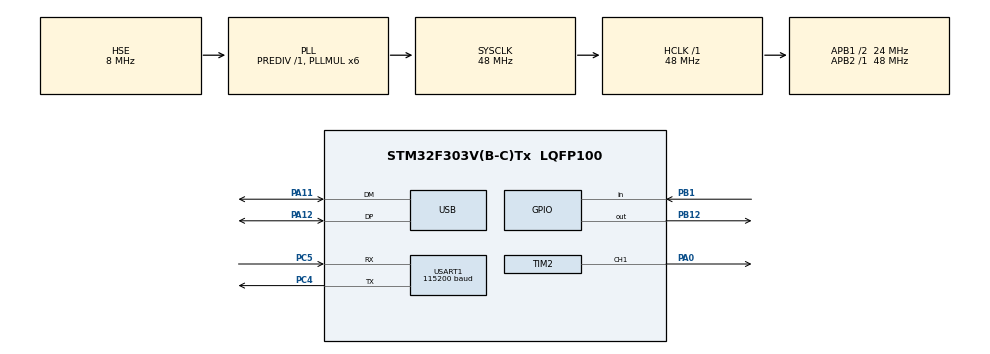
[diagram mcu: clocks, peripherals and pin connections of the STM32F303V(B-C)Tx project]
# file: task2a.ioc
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Mcu.Family=STM32F3
Mcu.Name=STM32F303V(B-C)Tx
Mcu.Package=LQFP100
NVIC.PriorityGroup=NVIC_PRIORITYGROUP_0
NVIC.USB_LP_CAN_RX0_IRQn=true\:0\:0\:false\:false\:true\:false\:true\:true
PA0.Signal=S_TIM2_CH1_ETR
PA11.Mode=Device
PA11.Signal=USB_DM
PA12.Mode=Device
PA12.Signal=USB_DP
PB1.Signal=GPIO_Input
PB12.Signal=GPIO_Output
PC4.Mode=Asynchronous
PC4.Signal=USART1_TX
PC5.Mode=Asynchronous
PC5.Signal=USART1_RX
PF0-OSC_IN.Mode=HSE-External-Oscillator
PF0-OSC_IN.Signal=RCC_OSC_IN
PF1-OSC_OUT.Mode=HSE-External-Oscillator
PF1-OSC_OUT.Signal=RCC_OSC_OUT
ProjectManager.HeapSize=0x200
ProjectManager.StackSize=0x400
ProjectManager.TargetToolchain=CMake
RCC.AHBFreq_Value=48000000
RCC.APB1CLKDivider=RCC_HCLK_DIV2
RCC.APB1Freq_Value=24000000
RCC.APB1TimFreq_Value=48000000
RCC.APB2Freq_Value=48000000
RCC.APB2TimFreq_Value=48000000
RCC.CortexFreq_Value=48000000
RCC.HCLKFreq_Value=48000000
RCC.HSE_VALUE=8000000
RCC.HSI_VALUE=8000000
RCC.LSE_VALUE=32768
RCC.PLLMUL=RCC_PLL_MUL6
RCC.PLLSourceVirtual=RCC_PLLSOURCE_HSE
RCC.SYSCLKFreq_VALUE=48000000
RCC.SYSCLKSourceVirtual=RCC_SYSCLKSOURCE_PLLCLK
RCC.USBFreq_Value=48000000
SH.S_TIM2_CH1_ETR.0=TIM2_CH1,PWM Generation1 CH1
TIM2.Channel-PWM\ Generation1\ CH1=TIM_CHANNEL_1
TIM2.Period=99
TIM2.Prescaler=47
TIM2.Pulse-PWM\ Generation1\ CH1=50
TIM3.Prescaler=71
USART1.BaudRate=115200
USART1.VirtualMode-Asynchronous=VM_ASYNC
USB_DEVICE.CLASS_NAME_FS=CDC
USB_DEVICE.VirtualMode=Cdc
USB_DEVICE.VirtualModeFS=Cdc_FS
VP_TIM2_VS_ClockSourceINT.Mode=Internal
VP_TIM3_VS_ClockSourceINT.Mode=Internal
VP_USB_DEVICE_VS_USB_DEVICE_CDC_FS.Mode=CDC_FS
board=STM32F3DISCOVERY

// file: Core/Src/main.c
/* USER CODE BEGIN Header */
/**
  ******************************************************************************
  * @file           : main.c
  * @brief          : Main program body
  ******************************************************************************
  * @attention
  *
  * Copyright (c) 2025 STMicroelectronics.
  * All rights reserved.
  *
  * This software is licensed under terms that can be found in the LICENSE file
  * in the root directory of this software component.
  * If no LICENSE file comes with this software, it is provided AS-IS.
  *
  ******************************************************************************
  */
/* USER CODE END Header */
#include "main.h"
#include "usb_device.h"

TIM_HandleTypeDef htim2;
TIM_HandleTypeDef htim3;

UART_HandleTypeDef huart1;

/* USER CODE BEGIN PV */
char msg[50];
float RPM = 0;
/* USER CODE END PV */

void SystemClock_Config(void);
static void MX_GPIO_Init(void);
static void MX_TIM2_Init(void);
static void MX_TIM3_Init(void);
static void MX_USART1_UART_Init(void);

int main(void)
{

  /* MCU Configuration--------------------------------------------------------*/

  /* Reset of all peripherals, Initializes the Flash interface and the Systick. */
  HAL_Init();

  /* Configure the system clock */
  SystemClock_Config();

  /* Initialize all configured peripherals */
  MX_GPIO_Init();
  MX_TIM2_Init();
  MX_TIM3_Init();
  MX_USART1_UART_Init();
  MX_USB_DEVICE_Init();
  /* USER CODE BEGIN 2 */

  HAL_TIM_PWM_Start(&htim2, TIM_CHANNEL_1);
  HAL_GPIO_WritePin(GPIOB, GPIO_PIN_12,1);

  /* USER CODE END 2 */

  /* Infinite loop */
  /* USER CODE BEGIN WHILE */
  while (1)
{
  // Wait for first edge
  while (HAL_GPIO_ReadPin(GPIOB, GPIO_PIN_1) == GPIO_PIN_RESET);
  while (HAL_GPIO_ReadPin(GPIOB, GPIO_PIN_1) == GPIO_PIN_SET); // Wait for falling edge

  __HAL_TIM_SET_COUNTER(&htim3, 0);               // Reset TIM3 counter
  HAL_TIM_Base_Start(&htim3);                     // Start timer

  // Wait for second edge
  while (HAL_GPIO_ReadPin(GPIOB, GPIO_PIN_1) == GPIO_PIN_RESET);
  while (HAL_GPIO_ReadPin(GPIOB, GPIO_PIN_1) == GPIO_PIN_SET); // Wait for falling edge again

  HAL_TIM_Base_Stop(&htim3);                      // Stop timer
  uint32_t captured_ticks = __HAL_TIM_GET_COUNTER(&htim3);  // Get the counter value

  float frequency = 0;
  if (captured_ticks != 0)
    frequency = 1000000.0f / captured_ticks;

  RPM = (frequency / 360.0f) * 60.0f;
  snprintf(msg, sizeof(msg), "Frequency = %.2f Hz, RPM = %.2f\r\n", frequency, RPM);
  HAL_UART_Transmit(&huart1, (uint8_t*)msg, strlen(msg), HAL_MAX_DELAY);

  /* USER CODE END 3 */
}

void SystemClock_Config(void)
{
  RCC_OscInitTypeDef RCC_OscInitStruct = {0};
  RCC_ClkInitTypeDef RCC_ClkInitStruct = {0};
  RCC_PeriphCLKInitTypeDef PeriphClkInit = {0};

  /** Initializes the RCC Oscillators according to the specified parameters
  * in the RCC_OscInitTypeDef structure.
  */
  RCC_OscInitStruct.OscillatorType = RCC_OSCILLATORTYPE_HSE;
  RCC_OscInitStruct.HSEState = RCC_HSE_ON;
  RCC_OscInitStruct.HSEPredivValue = RCC_HSE_PREDIV_DIV1;
  RCC_OscInitStruct.HSIState = RCC_HSI_ON;
  RCC_OscInitStruct.PLL.PLLState = RCC_PLL_ON;
  RCC_OscInitStruct.PLL.PLLSource = RCC_PLLSOURCE_HSE;
  RCC_OscInitStruct.PLL.PLLMUL = RCC_PLL_MUL6;
  if (HAL_RCC_OscConfig(&RCC_OscInitStruct) != HAL_OK)
  {
    Error_Handler();
  }

  /** Initializes the CPU, AHB and APB buses clocks
  */
  RCC_ClkInitStruct.ClockType = RCC_CLOCKTYPE_HCLK|RCC_CLOCKTYPE_SYSCLK
                              |RCC_CLOCKTYPE_PCLK1|RCC_CLOCKTYPE_PCLK2;
  RCC_ClkInitStruct.SYSCLKSource = RCC_SYSCLKSOURCE_PLLCLK;
  RCC_ClkInitStruct.AHBCLKDivider = RCC_SYSCLK_DIV1;
  RCC_ClkInitStruct.APB1CLKDivider = RCC_HCLK_DIV2;
  RCC_ClkInitStruct.APB2CLKDivider = RCC_HCLK_DIV1;

  if (HAL_RCC_ClockConfig(&RCC_ClkInitStruct, FLASH_LATENCY_1) != HAL_OK)
  {
    Error_Handler();
  }
  PeriphClkInit.PeriphClockSelection = RCC_PERIPHCLK_USB|RCC_PERIPHCLK_USART1;
  PeriphClkInit.Usart1ClockSelection = RCC_USART1CLKSOURCE_PCLK2;
  PeriphClkInit.USBClockSelection = RCC_USBCLKSOURCE_PLL;
  if (HAL_RCCEx_PeriphCLKConfig(&PeriphClkInit) != HAL_OK)
  {
    Error_Handler();
  }
}

static void MX_TIM2_Init(void)
{

  TIM_ClockConfigTypeDef sClockSourceConfig = {0};
  TIM_MasterConfigTypeDef sMasterConfig = {0};
  TIM_OC_InitTypeDef sConfigOC = {0};

  htim2.Instance = TIM2;
  htim2.Init.Prescaler = 71;
  htim2.Init.CounterMode = TIM_COUNTERMODE_UP;
  htim2.Init.Period = 99;
  htim2.Init.ClockDivision = TIM_CLOCKDIVISION_DIV1;
  htim2.Init.AutoReloadPreload = TIM_AUTORELOAD_PRELOAD_DISABLE;
  if (HAL_TIM_Base_Init(&htim2) != HAL_OK)
  {
    Error_Handler();
  }
  sClockSourceConfig.ClockSource = TIM_CLOCKSOURCE_INTERNAL;
  if (HAL_TIM_ConfigClockSource(&htim2, &sClockSourceConfig) != HAL_OK)
  {
    Error_Handler();
  }
  if (HAL_TIM_PWM_Init(&htim2) != HAL_OK)
  {
    Error_Handler();
  }
  sMasterConfig.MasterOutputTrigger = TIM_TRGO_RESET;
  sMasterConfig.MasterSlaveMode = TIM_MASTERSLAVEMODE_DISABLE;
  if (HAL_TIMEx_MasterConfigSynchronization(&htim2, &sMasterConfig) != HAL_OK)
  {
    Error_Handler();
  }
  sConfigOC.OCMode = TIM_OCMODE_PWM1;
  sConfigOC.Pulse = 50;
  sConfigOC.OCPolarity = TIM_OCPOLARITY_HIGH;
  sConfigOC.OCFastMode = TIM_OCFAST_DISABLE;
  if (HAL_TIM_PWM_ConfigChannel(&htim2, &sConfigOC, TIM_CHANNEL_1) != HAL_OK)
  {
    Error_Handler();
  }
  HAL_TIM_MspPostInit(&htim2);

}

static void MX_TIM3_Init(void)
{

  TIM_ClockConfigTypeDef sClockSourceConfig = {0};
  TIM_MasterConfigTypeDef sMasterConfig = {0};

  htim3.Instance = TIM3;
  htim3.Init.Prescaler = 47;
  htim3.Init.CounterMode = TIM_COUNTERMODE_UP;
  htim3.Init.Period = 65535;
  htim3.Init.ClockDivision = TIM_CLOCKDIVISION_DIV1;
  htim3.Init.AutoReloadPreload = TIM_AUTORELOAD_PRELOAD_DISABLE;
  if (HAL_TIM_Base_Init(&htim3) != HAL_OK)
  {
    Error_Handler();
  }
  sClockSourceConfig.ClockSource = TIM_CLOCKSOURCE_INTERNAL;
  if (HAL_TIM_ConfigClockSource(&htim3, &sClockSourceConfig) != HAL_OK)
  {
    Error_Handler();
  }
  sMasterConfig.MasterOutputTrigger = TIM_TRGO_RESET;
  sMasterConfig.MasterSlaveMode = TIM_MASTERSLAVEMODE_DISABLE;
  if (HAL_TIMEx_MasterConfigSynchronization(&htim3, &sMasterConfig) != HAL_OK)
  {
    Error_Handler();
  }

}

static void MX_USART1_UART_Init(void)
{

  huart1.Instance = USART1;
  huart1.Init.BaudRate = 115200;
  huart1.Init.WordLength = UART_WORDLENGTH_8B;
  huart1.Init.StopBits = UART_STOPBITS_1;
  huart1.Init.Parity = UART_PARITY_NONE;
  huart1.Init.Mode = UART_MODE_TX_RX;
  huart1.Init.HwFlowCtl = UART_HWCONTROL_NONE;
  huart1.Init.OverSampling = UART_OVERSAMPLING_16;
  huart1.Init.OneBitSampling = UART_ONE_BIT_SAMPLE_DISABLE;
  huart1.AdvancedInit.AdvFeatureInit = UART_ADVFEATURE_NO_INIT;
  if (HAL_UART_Init(&huart1) != HAL_OK)
  {
    Error_Handler();
  }

}

static void MX_GPIO_Init(void)
{
  GPIO_InitTypeDef GPIO_InitStruct = {0};

  /* GPIO Ports Clock Enable */
  __HAL_RCC_GPIOF_CLK_ENABLE();
  __HAL_RCC_GPIOA_CLK_ENABLE();
  __HAL_RCC_GPIOC_CLK_ENABLE();
  __HAL_RCC_GPIOB_CLK_ENABLE();

  /*Configure GPIO pin Output Level */
  HAL_GPIO_WritePin(GPIOB, GPIO_PIN_12, GPIO_PIN_RESET);

  /*Configure GPIO pin : PB1 */
  GPIO_InitStruct.Pin = GPIO_PIN_1;
  GPIO_InitStruct.Mode = GPIO_MODE_INPUT;
  GPIO_InitStruct.Pull = GPIO_NOPULL;
  HAL_GPIO_Init(GPIOB, &GPIO_InitStruct);

  /*Configure GPIO pin : PB12 */
  GPIO_InitStruct.Pin = GPIO_PIN_12;
  GPIO_InitStruct.Mode = GPIO_MODE_OUTPUT_PP;
  GPIO_InitStruct.Pull = GPIO_NOPULL;
  GPIO_InitStruct.Speed = GPIO_SPEED_FREQ_LOW;
  HAL_GPIO_Init(GPIOB, &GPIO_InitStruct);

  /* USER CODE BEGIN MX_GPIO_Init_2 */
// Configure PA0 (TIM2_CH1) as alternate function (AF1)
GPIO_InitStruct.Pin = GPIO_PIN_0;
GPIO_InitStruct.Mode = GPIO_MODE_AF_PP;
GPIO_InitStruct.Pull = GPIO_NOPULL;
GPIO_InitStruct.Speed = GPIO_SPEED_FREQ_LOW;
GPIO_InitStruct.Alternate = GPIO_AF1_TIM2;
HAL_GPIO_Init(GPIOA, &GPIO_InitStruct);

  /* USER CODE END MX_GPIO_Init_2 */
}

void Error_Handler(void)
{
  __disable_irq();
  while (1)
  {
  }
}
